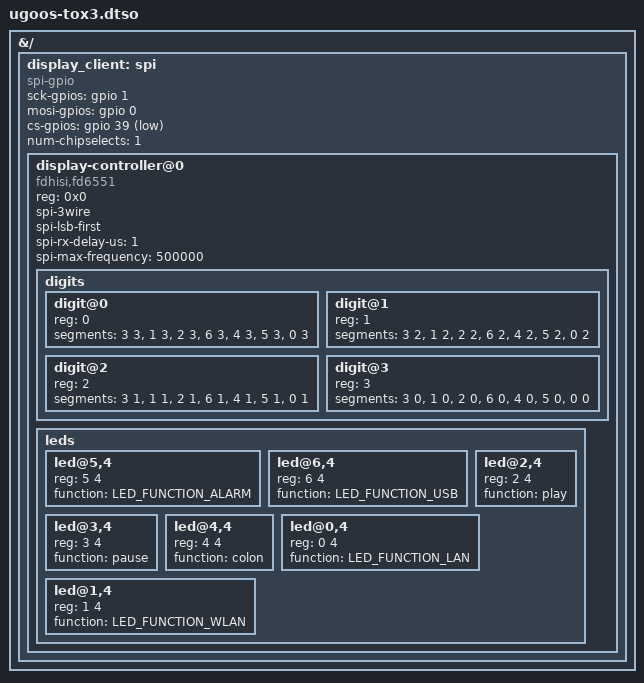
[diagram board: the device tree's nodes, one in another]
/dts-v1/;
/plugin/;

#include <dt-bindings/gpio/gpio.h>
#include <dt-bindings/leds/common.h>

&{/} {

	display_client: spi {
		#address-cells = <1>;
		#size-cells = <0>;
		compatible = "spi-gpio";
		sck-gpios = <&gpio 1 GPIO_ACTIVE_HIGH>;
		mosi-gpios = <&gpio 0 GPIO_ACTIVE_HIGH>;
		cs-gpios = <&gpio 39 GPIO_ACTIVE_LOW>;
		num-chipselects = <1>;

		display-controller@0 {
			compatible = "fdhisi,fd6551";
			reg = <0x0>;
			spi-3wire;
			spi-lsb-first;
			spi-rx-delay-us = <1>;
			spi-max-frequency = <500000>;

			digits {
				#address-cells = <1>;
				#size-cells = <0>;
				digit@0 {
					reg = <0>;
					segments = <3 3>,
						   <1 3>,
						   <2 3>,
						   <6 3>,
						   <4 3>,
						   <5 3>,
						   <0 3>;
				};
				digit@1 {
					reg = <1>;
					segments = <3 2>,
						   <1 2>,
						   <2 2>,
						   <6 2>,
						   <4 2>,
						   <5 2>,
						   <0 2>;
				};
				digit@2 {
					reg = <2>;
					segments = <3 1>,
						   <1 1>,
						   <2 1>,
						   <6 1>,
						   <4 1>,
						   <5 1>,
						   <0 1>;
				};
				digit@3 {
					reg = <3>;
					segments = <3 0>,
						   <1 0>,
						   <2 0>,
						   <6 0>,
						   <4 0>,
						   <5 0>,
						   <0 0>;
				};
			};

			leds {
				#address-cells = <2>;
				#size-cells = <0>;
				led@5,4 {
					reg = <5 4>;
					function = LED_FUNCTION_ALARM;
				};
				led@6,4 {
					reg = <6 4>;
					function = LED_FUNCTION_USB;
				};
				led@2,4 {
					reg = <2 4>;
					function = "play";
				};
				led@3,4 {
					reg = <3 4>;
					function = "pause";
				};
				led@4,4 {
					reg = <4 4>;
					function = "colon";
				};
				led@0,4 {
					reg = <0 4>;
					function = LED_FUNCTION_LAN;
				};
				led@1,4 {
					reg = <1 4>;
					function = LED_FUNCTION_WLAN;
				};
			};
		};
	};
};
